# AVR16EB20 device description
Architecture: AVR8X; Family: AVREB
Registers are 8-bit, read-write, reset 0x0 unless marked. A register's access mark holds for its fields unless they carry their own. Offsets are from the block's base; [hi:lo] are bit positions; {n}, {i} and the like mark numbered series; 'fields as' and 'values as' point back to an identical list; <NAME> marks a mode.

## SLPCTRL — Sleep Controller
Instances: SLPCTRL 0x0050
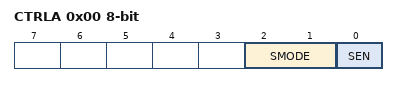
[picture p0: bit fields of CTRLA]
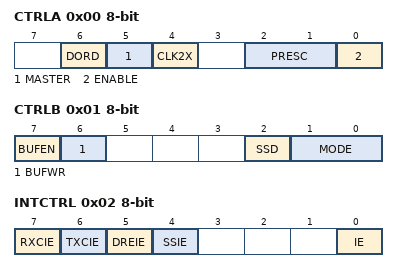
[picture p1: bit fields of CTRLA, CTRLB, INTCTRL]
0x00 CTRLA — Control A
  [2:1] SMODE — Sleep mode
    0=IDLE (Idle mode); 1=STDBY (Standby Mode); 2=PDOWN (Power-down Mode)
  [0] SEN — Sleep enable

## SPI — Serial Peripheral Interface
Instances: SPI0 0x0940
0x00 CTRLA — Control A
  [6] DORD — Data Order Setting
  [5] MASTER — Host Operation Enable
  [4] CLK2X — Enable Double Speed
  [2:1] PRESC — Prescaler
    0=DIV4 (CLK_PER / 4); 1=DIV16 (CLK_PER / 16); 2=DIV64 (CLK_PER / 64); 3=DIV128 (CLK_PER / 128)
  [0] ENABLE — Enable Module
0x01 CTRLB — Control B
  [7] BUFEN — Buffer Mode Enable
  [6] BUFWR — Buffer Mode Wait for Receive
  [2] SSD — SPI Select Disable
  [1:0] MODE — SPI Mode
    {v}=SPI Mode {v} (v=0..3)
0x02 INTCTRL — Interrupt Control
  [7] RXCIE — Receive Complete Interrupt Enable
  [6] TXCIE — Transfer Complete Interrupt Enable
  [5] DREIE — Data Register Empty Interrupt Enable
  [4] SSIE — SPI Select Trigger Interrupt Enable
  [0] IE — Interrupt Enable
0x03 INTFLAGS (modes: DEFAULT when SPI.CTRLB.BUFEN=0; BUFFERED when SPI.CTRLB.BUFEN=1) — Interrupt Flags
  [7] RXCIF <BUFFERED> — Receive Complete Interrupt Flag
  [6] TXCIF <BUFFERED> — Transfer Complete Interrupt Flag
  [5] DREIF <BUFFERED> — Data Register Empty Interrupt Flag
  [4] SSIF <BUFFERED> — SPI Select Trigger Interrupt Flag
  [0] BUFOVF <BUFFERED> — Buffer Overflow
  [7] IF <DEFAULT> — Interrupt Flag
  [6] WRCOL <DEFAULT> — Write Collision
0x04 DATA reset not defined

## SYSCFG — System Configuration Registers
Instances: SYSCFG 0x0F00
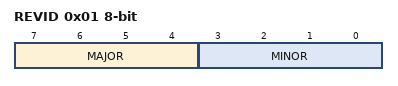
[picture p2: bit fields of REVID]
0x01 REVID ro reset not defined — Revision ID
  [7:4] MAJOR — Major Revision
  [3:0] MINOR — Minor Revision

## TCB — 16-bit Timer/Counter Type B
Instances: TCB0 0x0B00, TCB1 0x0B10
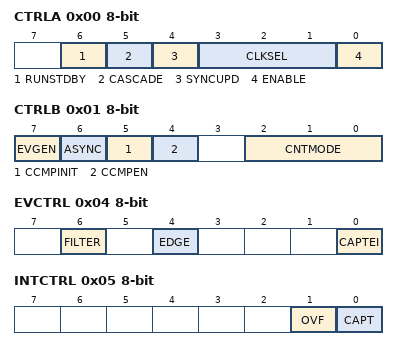
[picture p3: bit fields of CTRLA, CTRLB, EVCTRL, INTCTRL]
0x00 CTRLA — Control A
  [6] RUNSTDBY — Run Standby
  [5] CASCADE — Cascade two timers
  [4] SYNCUPD — Synchronize Update
  [3:1] CLKSEL — Clock Select
    0=DIV1 (CLK_PER); 1=DIV2 (CLK_PER/2); 2=TCE0 (Use CLK_TCE from TCE0); 7=EVENT (Count on event edge)
  [0] ENABLE
0x01 CTRLB — Control B
  [7] EVGEN — Event Generation
    0=PULSE (Event is generated as pulse at compare match or capture); 1=WAVEFORM (Event is generated as waveform for modes with waveform)
  [6] ASYNC — Asynchronous Enable
  [5] CCMPINIT — Pin Initial State
  [4] CCMPEN — Pin Output Enable
  [2:0] CNTMODE — Timer Mode
    0=INT (Periodic Interrupt); 1=TIMEOUT (Periodic Timeout); 2=CAPT (Input Capture Event); 3=FRQ (Input Capture Frequency measurement); 4=PW (Input Capture Pulse-Width measurement); 5=FRQPW (Input Capture Frequency and Pulse-Width measurement); 6=SINGLE (Single Shot); 7=PWM8 (8-bit PWM)
0x02 CTRLC — Control C
  [2:0] CNTSIZE — Counter Size
    0=16BITS (16-bit CNT. MAX=16'hFFFF); 1=15BITS (15-bit CNT. MAX=16'h7FFF); 2=14BITS (14-bit CNT. MAX=16'h3FFF); 3=13BITS (13-bit CNT. MAX=16'h1FFF); 4=12BITS (12-bit CNT. MAX=16'h0FFF); 5=11BITS (11-bit CNT. MAX=16'h07FF); 6=10BITS (10-bit CNT. MAX=16'h03FF); 7=9BITS (9-bit CNT. MAX=16'h01FF)
0x04 EVCTRL — Event Control
  [6] FILTER — Input Capture Noise Cancellation Filter
  [4] EDGE — Event Edge
  [0] CAPTEI — Event Input Enable
0x05 INTCTRL — Interrupt Control
  [1] OVF — Overflow
  [0] CAPT — Capture or Timeout
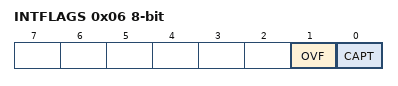
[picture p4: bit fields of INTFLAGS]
0x06 INTFLAGS — Interrupt Flags
  [1] OVF — Overflow
  [0] CAPT — Capture or Timeout
0x07 STATUS ro
  [0] RUN
0x08 DBGCTRL — Debug Control
  [0] DBGRUN — Debug Run
0x09 TEMP reset not defined — Temporary Value
0x0A CNT 16-bit — Count
0x0C CCMP 16-bit reset not defined — Compare or Capture

## TCF — 24-bit Timer/Counter for frequency generation
Instances: TCF0 0x0C00
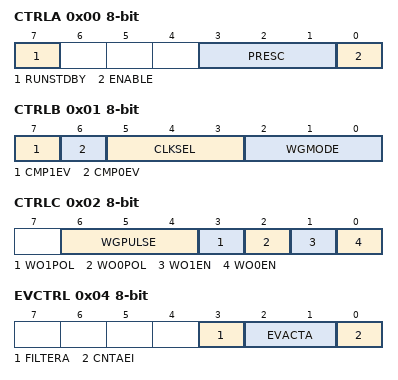
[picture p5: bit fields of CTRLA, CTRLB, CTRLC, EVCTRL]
0x00 CTRLA — Control A
  [7] RUNSTDBY — Run Standby
  [3:1] PRESC — Clock Prescaler
    0=DIV1 (Runs directly on Clock Source); 1=DIV2 (Divide clock source by 2); 2=DIV4 (Divide clock source by 4); 3=DIV8 (Divide clock source by 8); 4=DIV16 (Divide clock source by 16); 5=DIV32 (Divide clock source by 32); 6=DIV64 (Divide clock source by 64); 7=DIV128 (Divide clock source by 128)
  [0] ENABLE
0x01 CTRLB — Control B
  [7] CMP1EV — Compare 1 Event Generation
    0=PULSE (Event is generated as pulse); 1=WAVEFORM (Waveform is used as event output)
  [6] CMP0EV — Compare 0 Event Generation
    values as CMP1EV
  [5:3] CLKSEL — Clock Select
    0=CLKPER (Peripheral Clock); 1=EVENT (Event as clock source); 2=OSCHF (Internal High Frequency Oscillator); 3=OSC32K (Internal 32.768 kHz Oscillator); 5=PLL
  [2:0] WGMODE — Waveform Generation Mode
    0=FRQ (Frequency); 1=NCOPF (Numerically Controlled Oscillator Pulse-Frequency); 2=NCOFDC (Numerically Controlled Oscillator Fixed Duty Cycle); 7=PWM8 (8-bit PWM)
0x02 CTRLC — Control C
  [6:4] WGPULSE — Waveform Generation Pulse Length
    0=CLK1 (High pulse duration is 1 clock period); 1=CLK2 (High pulse duration is 2 clock period); 2=CLK4 (High pulse duration is 4 clock period); 3=CLK8 (High pulse duration is 8 clock period); 4=CLK16 (High pulse duration is 16 clock period); 5=CLK32 (High pulse duration is 32 clock period); 6=CLK64 (High pulse duration is 64 clock period); 7=CLK128 (High pulse duration is 128 clock period)
  [3] WO1POL — Waveform Output 1 Polarity
    0=NORMAL (Waveform output set on update and cleared on match); 1=INVERSE (Waveform output cleared on update and set on match)
  [2] WO0POL — Waveform Output 0 Polarity
    values as WO1POL
  [1] WO1EN — Waveform Output 1 Enable
  [0] WO0EN — Waveform Output 0 Enable
0x03 CTRLD — Control D
  [1:0] CMD — Command
    0=NONE (No command); 1=UPDATE (Force update); 2=RESTART (Force restart)
0x04 EVCTRL — Event Control
  [3] FILTERA — Event A Filter
  [2:1] EVACTA — Event Action A
    0=RESTART (Restart Counter); 1=BLANK (Mask waveform output to '0')
  [0] CNTAEI — Event A Input Enable
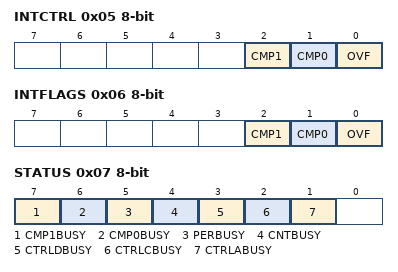
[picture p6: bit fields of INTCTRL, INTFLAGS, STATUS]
0x05 INTCTRL — Interrupt Control
  [2] CMP1 — Compare 1 Interrupt Enable
  [1] CMP0 — Compare 0 Interrupt Enable
  [0] OVF — Overflow
0x06 INTFLAGS — Interrupt Flags
  [2] CMP1 — Compare 1 Flag
  [1] CMP0 — Compare 0 Flag
  [0] OVF — Overflow Flag
0x07 STATUS ro
  [7] CMP1BUSY — Compare 1 Synchronization Busy
  [6] CMP0BUSY — Compare 0 Synchronization Busy
  [5] PERBUSY — Period Synchronization Busy
  [4] CNTBUSY — Counter Synchronization Busy
  [3] CTRLDBUSY — Control D Synchronization Busy
  [2] CTRLCBUSY — Control B Synchronization Busy
  [1] CTRLABUSY — Control A Synchronization Busy
0x0D DBGCTRL — Debug Control
  [0] DBGRUN — Debug Run
0x10 CNT 32-bit — Count
  [23:0] CNT — Counter
0x14 CMP 32-bit — Compare
  [23:0] CMP
